# haltium_cellcore register map
Vendor: Nordic Semiconductor; Series: nRFHaltium; File version: 1
CPU: CM33 r0p4, little endian, MPU, FPU, 3 interrupt priority bits, 480 interrupts
Registers are 32-bit, read-write, reset 0x0 unless marked. A register's access mark holds for its fields unless they carry their own. Offsets are from the block's base; [hi:lo] are bit positions; lines under a group give offsets from that group; 'fields as' and 'values as' point back to an identical list.

## GLOBAL_TWIM120_NS — I2C compatible Two-Wire Master Interface with EasyDMA 0
Base 0x4F8E8000
Same registers: GLOBAL_TWIM130_NS 0x4F9A5000 (alternate view of GLOBAL_SPIM130_NS), GLOBAL_TWIM131_NS 0x4F9A6000 (alternate view of GLOBAL_SPIM131_NS), GLOBAL_TWIM132_NS 0x4F9B5000 (alternate view of GLOBAL_SPIM132_NS), GLOBAL_TWIM133_NS 0x4F9B6000 (alternate view of GLOBAL_SPIM133_NS), GLOBAL_TWIM134_NS 0x4F9C5000 (alternate view of GLOBAL_SPIM134_NS), GLOBAL_TWIM135_NS 0x4F9C6000 (alternate view of GLOBAL_SPIM135_NS), GLOBAL_TWIM136_NS 0x4F9D5000 (alternate view of GLOBAL_SPIM136_NS), GLOBAL_TWIM137_NS 0x4F9D6000 (alternate view of GLOBAL_SPIM137_NS), GLOBAL_TWIM120_S 0x5F8E8000, GLOBAL_TWIM130_S 0x5F9A5000 (alternate view of GLOBAL_SPIM130_S), GLOBAL_TWIM131_S 0x5F9A6000 (alternate view of GLOBAL_SPIM131_S), GLOBAL_TWIM132_S 0x5F9B5000 (alternate view of GLOBAL_SPIM132_S), GLOBAL_TWIM133_S 0x5F9B6000 (alternate view of GLOBAL_SPIM133_S), GLOBAL_TWIM134_S 0x5F9C5000 (alternate view of GLOBAL_SPIM134_S), GLOBAL_TWIM135_S 0x5F9C6000 (alternate view of GLOBAL_SPIM135_S), GLOBAL_TWIM136_S 0x5F9D5000 (alternate view of GLOBAL_SPIM136_S), GLOBAL_TWIM137_S 0x5F9D6000 (alternate view of GLOBAL_SPIM137_S)
0x00 TASKS_STARTRX wo — Start TWI receive sequence
  [0] TASKS_STARTRX
    1=Trigger task
0x08 TASKS_STARTTX wo — Start TWI transmit sequence
  [0] TASKS_STARTTX
    1=Trigger task
0x14 TASKS_STOP wo — Stop TWI transaction. Must be issued while the TWI master is not suspended.
  [0] TASKS_STOP
    1=Trigger task
0x1C TASKS_SUSPEND wo — Suspend TWI transaction
  [0] TASKS_SUSPEND
    1=Trigger task
0x20 TASKS_RESUME wo — Resume TWI transaction
  [0] TASKS_RESUME
    1=Trigger task
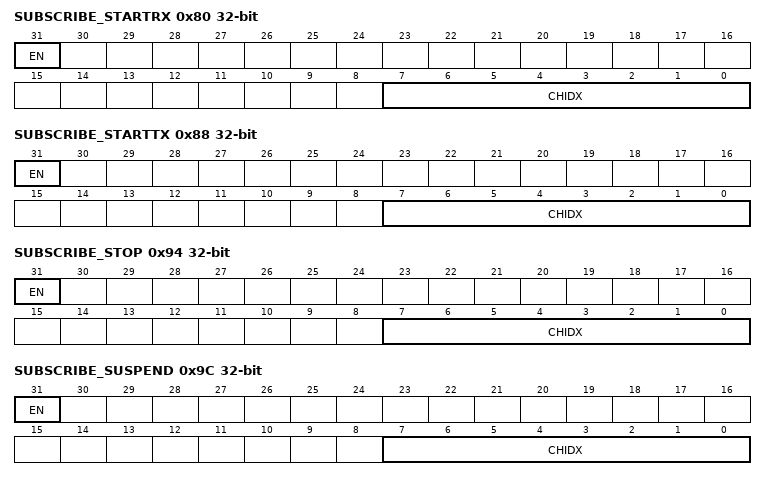
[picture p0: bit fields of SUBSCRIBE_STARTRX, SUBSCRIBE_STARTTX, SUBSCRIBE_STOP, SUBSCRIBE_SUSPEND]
0x80 SUBSCRIBE_STARTRX — Subscribe configuration for task STARTRX
  [31] EN
    0=Disabled (Disable subscription); 1=Enabled (Enable subscription)
  [7:0] CHIDX — DPPI channel that task STARTRX will subscribe to
0x88 SUBSCRIBE_STARTTX — Subscribe configuration for task STARTTX
  [31] EN
    values as SUBSCRIBE_STARTRX.EN
  [7:0] CHIDX — DPPI channel that task STARTTX will subscribe to
0x94 SUBSCRIBE_STOP — Subscribe configuration for task STOP
  [31] EN
    values as SUBSCRIBE_STARTRX.EN
  [7:0] CHIDX — DPPI channel that task STOP will subscribe to
0x9C SUBSCRIBE_SUSPEND — Subscribe configuration for task SUSPEND
  [31] EN
    values as SUBSCRIBE_STARTRX.EN
  [7:0] CHIDX — DPPI channel that task SUSPEND will subscribe to
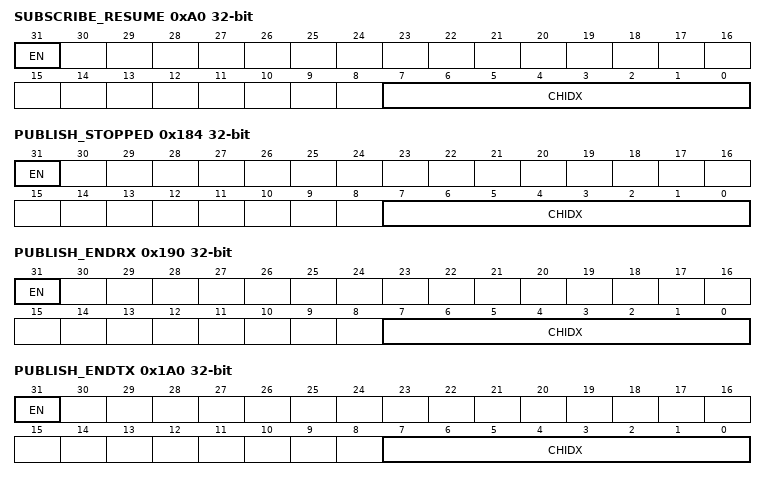
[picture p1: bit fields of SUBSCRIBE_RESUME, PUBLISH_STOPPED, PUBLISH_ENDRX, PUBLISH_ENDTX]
0xA0 SUBSCRIBE_RESUME — Subscribe configuration for task RESUME
  [31] EN
    values as SUBSCRIBE_STARTRX.EN
  [7:0] CHIDX — DPPI channel that task RESUME will subscribe to
0x104 EVENTS_STOPPED — TWI stopped
  [0] EVENTS_STOPPED
    0=NotGenerated (Event not generated); 1=Generated (Event generated)
0x110 EVENTS_ENDRX — End of RXD buffer access by EasyDMA
  [0] EVENTS_ENDRX
    values as EVENTS_STOPPED.EVENTS_STOPPED
0x120 EVENTS_ENDTX — END of TXD buffer access by EasyDMA
  [0] EVENTS_ENDTX
    values as EVENTS_STOPPED.EVENTS_STOPPED
0x124 EVENTS_ERROR — TWI error
  [0] EVENTS_ERROR
    values as EVENTS_STOPPED.EVENTS_STOPPED
0x138 EVENTS_BB — TWI byte boundary, generated before each byte that is sent or received
  [0] EVENTS_BB
    values as EVENTS_STOPPED.EVENTS_STOPPED
0x148 EVENTS_SUSPENDED — SUSPEND task has been issued, TWI traffic is now suspended.
  [0] EVENTS_SUSPENDED
    values as EVENTS_STOPPED.EVENTS_STOPPED
0x14C EVENTS_RXSTARTED — Receive sequence started
  [0] EVENTS_RXSTARTED
    values as EVENTS_STOPPED.EVENTS_STOPPED
0x150 EVENTS_TXSTARTED — Transmit sequence started
  [0] EVENTS_TXSTARTED
    values as EVENTS_STOPPED.EVENTS_STOPPED
0x15C EVENTS_LASTRX — Byte boundary, starting to receive the last byte
  [0] EVENTS_LASTRX
    values as EVENTS_STOPPED.EVENTS_STOPPED
0x160 EVENTS_LASTTX — Byte boundary, starting to transmit the last byte
  [0] EVENTS_LASTTX
    values as EVENTS_STOPPED.EVENTS_STOPPED
0x174 EVENTS_RXBUSERROR — This event is generated if an error occurs during the bus transfer. This event is generated on an AHB / AXI error response.
  [0] EVENTS_RXBUSERROR
    values as EVENTS_STOPPED.EVENTS_STOPPED
0x178 EVENTS_TXBUSERROR — This event is generated if an error occurs during the bus transfer. This event is generated on an AHB / AXI error response.
  [0] EVENTS_TXBUSERROR
    values as EVENTS_STOPPED.EVENTS_STOPPED
0x184 PUBLISH_STOPPED — Publish configuration for event STOPPED
  [31] EN
    0=Disabled (Disable publishing); 1=Enabled (Enable publishing)
  [7:0] CHIDX — DPPI channel that event STOPPED will publish to
0x190 PUBLISH_ENDRX — Publish configuration for event ENDRX
  [31] EN
    values as PUBLISH_STOPPED.EN
  [7:0] CHIDX — DPPI channel that event ENDRX will publish to
0x1A0 PUBLISH_ENDTX — Publish configuration for event ENDTX
  [31] EN
    values as PUBLISH_STOPPED.EN
  [7:0] CHIDX — DPPI channel that event ENDTX will publish to
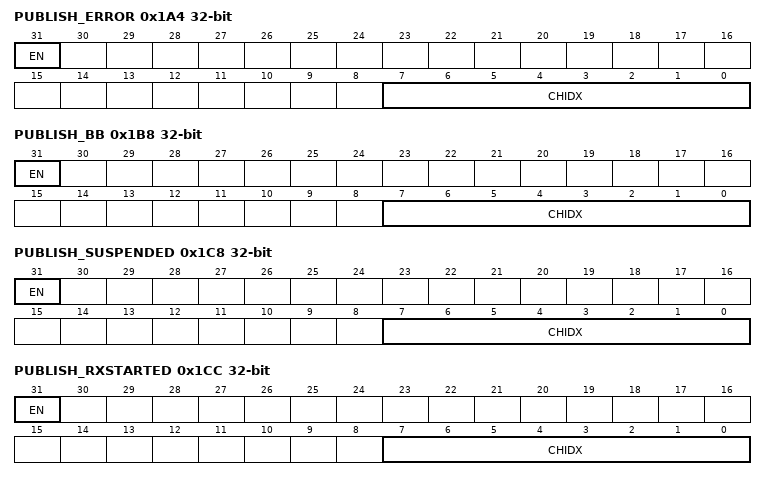
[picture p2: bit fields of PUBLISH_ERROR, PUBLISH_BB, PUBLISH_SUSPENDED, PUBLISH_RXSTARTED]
0x1A4 PUBLISH_ERROR — Publish configuration for event ERROR
  [31] EN
    values as PUBLISH_STOPPED.EN
  [7:0] CHIDX — DPPI channel that event ERROR will publish to
0x1B8 PUBLISH_BB — Publish configuration for event BB
  [31] EN
    values as PUBLISH_STOPPED.EN
  [7:0] CHIDX — DPPI channel that event BB will publish to
0x1C8 PUBLISH_SUSPENDED — Publish configuration for event SUSPENDED
  [31] EN
    values as PUBLISH_STOPPED.EN
  [7:0] CHIDX — DPPI channel that event SUSPENDED will publish to
0x1CC PUBLISH_RXSTARTED — Publish configuration for event RXSTARTED
  [31] EN
    values as PUBLISH_STOPPED.EN
  [7:0] CHIDX — DPPI channel that event RXSTARTED will publish to
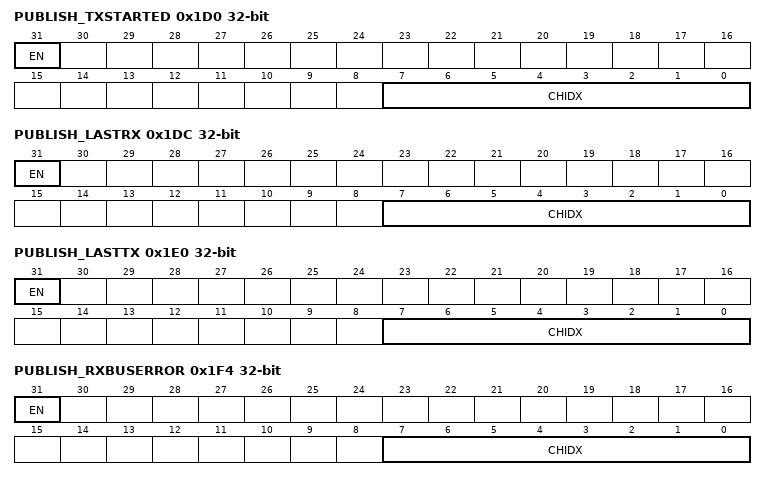
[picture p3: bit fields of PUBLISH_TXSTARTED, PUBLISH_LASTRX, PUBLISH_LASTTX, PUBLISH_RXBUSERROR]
0x1D0 PUBLISH_TXSTARTED — Publish configuration for event TXSTARTED
  [31] EN
    values as PUBLISH_STOPPED.EN
  [7:0] CHIDX — DPPI channel that event TXSTARTED will publish to
0x1DC PUBLISH_LASTRX — Publish configuration for event LASTRX
  [31] EN
    values as PUBLISH_STOPPED.EN
  [7:0] CHIDX — DPPI channel that event LASTRX will publish to
0x1E0 PUBLISH_LASTTX — Publish configuration for event LASTTX
  [31] EN
    values as PUBLISH_STOPPED.EN
  [7:0] CHIDX — DPPI channel that event LASTTX will publish to
0x1F4 PUBLISH_RXBUSERROR — Publish configuration for event RXBUSERROR
  [31] EN
    values as PUBLISH_STOPPED.EN
  [7:0] CHIDX — DPPI channel that event RXBUSERROR will publish to
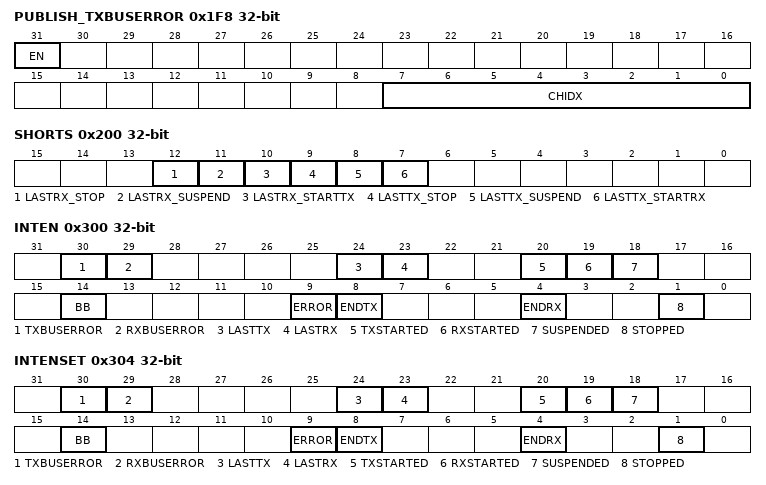
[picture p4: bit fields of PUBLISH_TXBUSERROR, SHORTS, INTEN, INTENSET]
0x1F8 PUBLISH_TXBUSERROR — Publish configuration for event TXBUSERROR
  [31] EN
    values as PUBLISH_STOPPED.EN
  [7:0] CHIDX — DPPI channel that event TXBUSERROR will publish to
0x200 SHORTS — Shortcuts between local events and tasks
  [all] fields
    0=Disabled (Disable shortcut); 1=Enabled (Enable shortcut)
  [12] LASTRX_STOP — Shortcut between event LASTRX and task STOP
  [11] LASTRX_SUSPEND — Shortcut between event LASTRX and task SUSPEND
  [10] LASTRX_STARTTX — Shortcut between event LASTRX and task STARTTX
  [9] LASTTX_STOP — Shortcut between event LASTTX and task STOP
  [8] LASTTX_SUSPEND — Shortcut between event LASTTX and task SUSPEND
  [7] LASTTX_STARTRX — Shortcut between event LASTTX and task STARTRX
0x300 INTEN — Enable or disable interrupt
  [all] fields
    0=Disabled; 1=Enabled
  [30] TXBUSERROR — Enable or disable interrupt for event TXBUSERROR
  [29] RXBUSERROR — Enable or disable interrupt for event RXBUSERROR
  [24] LASTTX — Enable or disable interrupt for event LASTTX
  [23] LASTRX — Enable or disable interrupt for event LASTRX
  [20] TXSTARTED — Enable or disable interrupt for event TXSTARTED
  [19] RXSTARTED — Enable or disable interrupt for event RXSTARTED
  [18] SUSPENDED — Enable or disable interrupt for event SUSPENDED
  [14] BB — Enable or disable interrupt for event BB
  [9] ERROR — Enable or disable interrupt for event ERROR
  [8] ENDTX — Enable or disable interrupt for event ENDTX
  [4] ENDRX — Enable or disable interrupt for event ENDRX
  [1] STOPPED — Enable or disable interrupt for event STOPPED
0x304 INTENSET — Enable interrupt
  [all] fields
    on read: 0=Disabled (Read: Disabled); 1=Enabled (Read: Enabled) | on write: 1=Set (Enable)
  [30] TXBUSERROR — Write '1' to enable interrupt for event TXBUSERROR
  [29] RXBUSERROR — Write '1' to enable interrupt for event RXBUSERROR
  [24] LASTTX — Write '1' to enable interrupt for event LASTTX
  [23] LASTRX — Write '1' to enable interrupt for event LASTRX
  [20] TXSTARTED — Write '1' to enable interrupt for event TXSTARTED
  [19] RXSTARTED — Write '1' to enable interrupt for event RXSTARTED
  [18] SUSPENDED — Write '1' to enable interrupt for event SUSPENDED
  [14] BB — Write '1' to enable interrupt for event BB
  [9] ERROR — Write '1' to enable interrupt for event ERROR
  [8] ENDTX — Write '1' to enable interrupt for event ENDTX
  [4] ENDRX — Write '1' to enable interrupt for event ENDRX
  [1] STOPPED — Write '1' to enable interrupt for event STOPPED
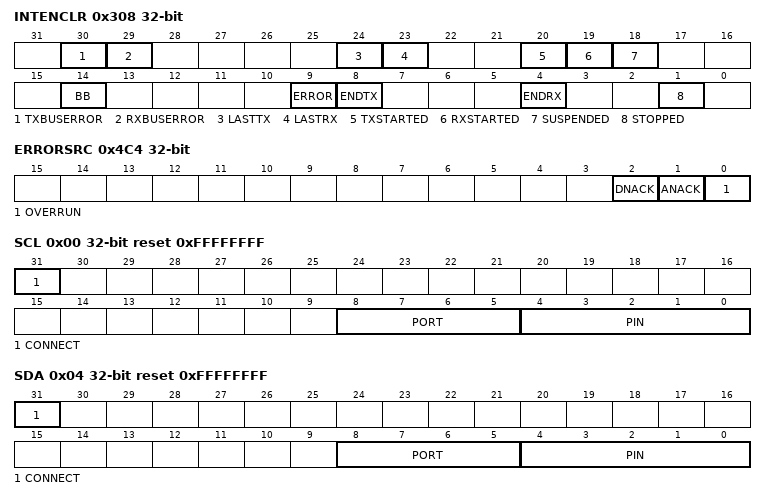
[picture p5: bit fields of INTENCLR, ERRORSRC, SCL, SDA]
0x308 INTENCLR — Disable interrupt
  [all] fields
    on read: 0=Disabled (Read: Disabled); 1=Enabled (Read: Enabled) | on write: 1=Clear (Disable)
  [30] TXBUSERROR — Write '1' to disable interrupt for event TXBUSERROR
  [29] RXBUSERROR — Write '1' to disable interrupt for event RXBUSERROR
  [24] LASTTX — Write '1' to disable interrupt for event LASTTX
  [23] LASTRX — Write '1' to disable interrupt for event LASTRX
  [20] TXSTARTED — Write '1' to disable interrupt for event TXSTARTED
  [19] RXSTARTED — Write '1' to disable interrupt for event RXSTARTED
  [18] SUSPENDED — Write '1' to disable interrupt for event SUSPENDED
  [14] BB — Write '1' to disable interrupt for event BB
  [9] ERROR — Write '1' to disable interrupt for event ERROR
  [8] ENDTX — Write '1' to disable interrupt for event ENDTX
  [4] ENDRX — Write '1' to disable interrupt for event ENDRX
  [1] STOPPED — Write '1' to disable interrupt for event STOPPED
0x4C4 ERRORSRC write-1-clears — Error source
  [all] fields
    0=NotReceived (Error did not occur); 1=Received (Error occurred)
  [2] DNACK — NACK received after sending a data byte (write '1' to clear)
  [1] ANACK — NACK received after sending the address (write '1' to clear)
  [0] OVERRUN — Overrun error
0x500 ENABLE — Enable TWIM
  [3:0] ENABLE — Enable or disable TWIM
    0=Disabled (Disable TWIM); 6=Enabled (Enable TWIM)
0x504 CONFIG — Configuration register
  [2:1] RG ro — Internal read-only status information
    1=K100 (100 kbit/s); 3=K1000 (1000 kbps)
0x508 PSEL group — Unspecified
  0x00 SCL reset 0xFFFFFFFF — Pin select for SCL signal
    [31] CONNECT — Connection
      1=Disconnected; 0=Connected
    [8:5] PORT — Port number
    [4:0] PIN — Pin number
  0x04 SDA reset 0xFFFFFFFF — Pin select for SDA signal
    fields as PSEL.SCL
0x520 FMPLUS reset 0xE000000 — FREQUENCY threshold for switch from regular mode to to FastMode+
  [31:0] THRESHOLD — Threshold value
0x524 FREQUENCY reset 0x4000000 — TWI frequency. Accuracy depends on the HFCLK source selected.
  [31:0] FREQUENCY — TWI master clock frequency
    0x1980000=K100 (100 kbps); 0x4000000=K250 (250 kbps); 0x6400000=K400 (400 kbps); 0xFF00000=K1000 (1000 kbps)
0x534 RXD group — RXD EasyDMA channel
  0x00 PTR — Data pointer
  0x04 MAXCNT — Maximum number of bytes in receive buffer
    [15:0] MAXCNT
  0x08 AMOUNT ro — Number of bytes transferred in the last transaction
    [15:0] AMOUNT — Number of bytes transferred in the last transaction. In case of NACK error, includes the NACK'ed byte.
  0x0C LIST — EasyDMA list type
    [2:0] LIST — List type
      0=Disabled (Disable EasyDMA list); 1=ArrayList (Use array list)
0x544 TXD group — TXD EasyDMA channel
  0x00 PTR — Data pointer
  0x04 MAXCNT — Maximum number of bytes in transmit buffer
    [15:0] MAXCNT
  0x08 AMOUNT ro — Number of bytes transferred in the last transaction
    fields as RXD.AMOUNT
  0x0C LIST — EasyDMA list type
    fields as RXD.LIST
0x588 ADDRESS — Address used in the TWI transfer
  [6:0] ADDRESS
0x5B0 DMA group — Unspecified
  0x00 RX group — Unspecified
    0x00 TERMINATEONBUSERROR — Terminate the transaction if a BUSERROR event is detected.
      [0] ENABLE
        0=Disabled; 1=Enabled
    0x04 BUSERRORADDRESS — Address of transaction that generated the last BUSERROR event.
      [31:0] ADDRESS
  0x08 TX group — Unspecified
    0x00 TERMINATEONBUSERROR — Terminate the transaction if a BUSERROR event is detected.
      [0] ENABLE
        0=Disabled; 1=Enabled
    0x04 BUSERRORADDRESS — Address of transaction that generated the last BUSERROR event.
      [31:0] ADDRESS
